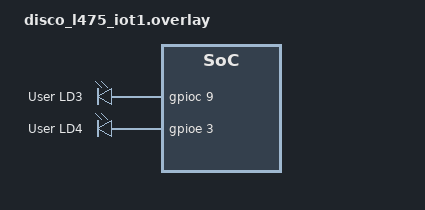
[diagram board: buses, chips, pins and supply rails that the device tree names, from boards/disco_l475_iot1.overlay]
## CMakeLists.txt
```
# SPDX-License-Identifier: Apache-2.0

cmake_minimum_required(VERSION 3.20.0)

find_package(Zephyr REQUIRED HINTS $ENV{ZEPHYR_BASE})
project(e_1_hello_world)

target_sources(app PRIVATE src/main.c src/hello.c)
target_include_directories(app PRIVATE include)
```

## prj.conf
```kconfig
CONFIG_LOG=y
CONFIG_GPIO=y
```

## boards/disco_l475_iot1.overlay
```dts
/ {
	leds {
	    green_led_3: led_3 {
			gpios = <&gpioc 9 GPIO_ACTIVE_HIGH>;
			label = "User LD3";
		};
    
    	green_led_4: led_4 {
			gpios = <&gpioe 3 GPIO_ACTIVE_HIGH>;
			label = "User LD4";
		};
	};

    aliases {
	    led2 = &green_led_3;
        led3 = &green_led_4;
	};

};
```

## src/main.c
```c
/*
 * Copyright (c) 2012-2014 Wind River Systems, Inc.
 *
 * SPDX-License-Identifier: Apache-2.0
 */

#include <stdio.h>
#include <zephyr/kernel.h>
#include <zephyr/logging/log.h>
#include <zephyr/drivers/gpio.h>
#include "hello.h"

#define LED0_NODE DT_ALIAS(led0)
#define LED1_NODE DT_ALIAS(led1)
#define LED2_NODE DT_ALIAS(led2)
#define LED3_NODE DT_ALIAS(led3)

static const struct gpio_dt_spec led_00 = GPIO_DT_SPEC_GET(LED0_NODE, gpios);
static const struct gpio_dt_spec led_01 = GPIO_DT_SPEC_GET(LED1_NODE, gpios);
static const struct gpio_dt_spec led_02 = GPIO_DT_SPEC_GET(LED2_NODE, gpios);
static const struct gpio_dt_spec led_03 = GPIO_DT_SPEC_GET(LED3_NODE, gpios);

LOG_MODULE_REGISTER(main,LOG_LEVEL_DBG);

int main(void)
{
	int ret;
	bool led_state = true;

	if(!gpio_is_ready_dt(&led_00) || !gpio_is_ready_dt(&led_01) || !gpio_is_ready_dt(&led_02) || !gpio_is_ready_dt(&led_03)) {
		return 0;
	}

	ret = gpio_pin_configure_dt(&led_00,GPIO_OUTPUT_ACTIVE);
	if(ret < 0) {
		return 0;
	}

	ret = gpio_pin_configure_dt(&led_01,GPIO_OUTPUT_ACTIVE);
	if(ret < 0) {
		return 0;
	}

	ret = gpio_pin_configure_dt(&led_02,GPIO_OUTPUT_ACTIVE);
	if(ret < 0) {
		return 0;
	}

	ret = gpio_pin_configure_dt(&led_03,GPIO_OUTPUT_ACTIVE);
	if(ret < 0) {
		return 0;
	}

	while(1)
	{
		LOG_DBG("Hiiii, this is from dbg");
		LOG_INF("Hiiii, this is from inf");
		LOG_WRN("Hiiii, this is from wrn");
		LOG_ERR("Hiiii, this is from err");

		printhello();

		ret = gpio_pin_toggle_dt(&led_00);
		if(ret < 0) {
			return 0;
		}

		ret = gpio_pin_toggle_dt(&led_01);
		if(ret < 0) {
			return 0;
		}

		ret = gpio_pin_toggle_dt(&led_02);
		if(ret < 0) {
			return 0;
		}

		ret = gpio_pin_toggle_dt(&led_03);
		if(ret < 0) {
			return 0;
		}
		led_state = !led_state;
		printk("LED %s\n",led_state ? "ON" : "OFF");

		k_msleep(5000);
	}

	return 0;
}
```

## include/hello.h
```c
#ifndef HELLO_H
#define HELLO_H

void printhello(void);

#endif
```

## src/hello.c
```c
#include <zephyr/kernel.h>

void  printhello(void)
{
	printk("Hello World! %s\n", CONFIG_BOARD_TARGET);
}
```
